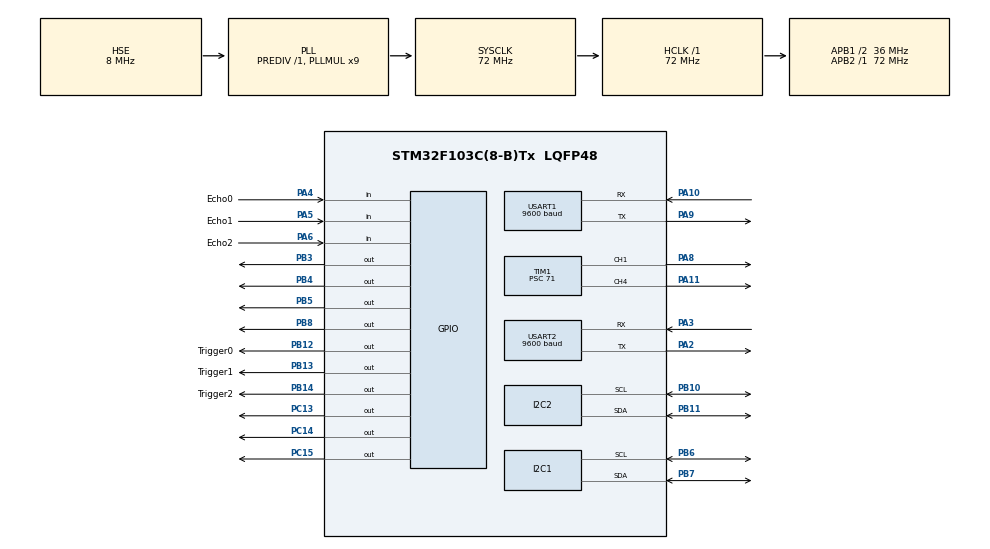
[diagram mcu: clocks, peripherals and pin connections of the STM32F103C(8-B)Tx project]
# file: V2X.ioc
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Mcu.Family=STM32F1
Mcu.Name=STM32F103C(8-B)Tx
Mcu.Package=LQFP48
NVIC.PriorityGroup=NVIC_PRIORITYGROUP_4
NVIC.TIM2_IRQn=true\:0\:0\:false\:false\:true\:true\:true\:true
NVIC.USART1_IRQn=true\:0\:0\:false\:false\:true\:true\:true\:true
PA10.Mode=Asynchronous
PA10.Signal=USART1_RX
PA11.Signal=S_TIM1_CH4
PA2.Mode=Asynchronous
PA2.Signal=USART2_TX
PA3.Mode=Asynchronous
PA3.Signal=USART2_RX
PA4.GPIO_Label=Echo0
PA4.Signal=GPIO_Input
PA5.GPIO_Label=Echo1
PA5.Signal=GPIO_Input
PA6.GPIO_Label=Echo2
PA6.Signal=GPIO_Input
PA8.Signal=S_TIM1_CH1
PA9.Mode=Asynchronous
PA9.Signal=USART1_TX
PB10.Mode=I2C
PB10.Signal=I2C2_SCL
PB11.Mode=I2C
PB11.Signal=I2C2_SDA
PB12.GPIO_Label=Trigger0
PB12.Signal=GPIO_Output
PB13.GPIO_Label=Trigger1
PB13.Signal=GPIO_Output
PB14.GPIO_Label=Trigger2
PB14.Signal=GPIO_Output
PB3.Signal=GPIO_Output
PB4.Signal=GPIO_Output
PB5.Signal=GPIO_Output
PB6.Mode=I2C
PB6.Signal=I2C1_SCL
PB7.Mode=I2C
PB7.Signal=I2C1_SDA
PB8.Signal=GPIO_Output
PC13-TAMPER-RTC.Signal=GPIO_Output
PC14-OSC32_IN.Signal=GPIO_Output
PC15-OSC32_OUT.Signal=GPIO_Output
PD0-OSC_IN.Mode=HSE-External-Oscillator
PD0-OSC_IN.Signal=RCC_OSC_IN
PD1-OSC_OUT.Mode=HSE-External-Oscillator
PD1-OSC_OUT.Signal=RCC_OSC_OUT
ProjectManager.HeapSize=0x200
ProjectManager.StackSize=0x400
ProjectManager.TargetToolchain=STM32CubeIDE
RCC.AHBFreq_Value=72000000
RCC.APB1CLKDivider=RCC_HCLK_DIV2
RCC.APB1Freq_Value=36000000
RCC.APB1TimFreq_Value=72000000
RCC.APB2Freq_Value=72000000
RCC.APB2TimFreq_Value=72000000
RCC.HCLKFreq_Value=72000000
RCC.PLLMUL=RCC_PLL_MUL9
RCC.PLLSourceVirtual=RCC_PLLSOURCE_HSE
RCC.SYSCLKFreq_VALUE=72000000
RCC.SYSCLKSource=RCC_SYSCLKSOURCE_PLLCLK
RCC.USBFreq_Value=72000000
SH.S_TIM1_CH1.0=TIM1_CH1,PWM Generation1 CH1
SH.S_TIM1_CH4.0=TIM1_CH4,PWM Generation4 CH4
TIM1.Channel-PWM\ Generation1\ CH1=TIM_CHANNEL_1
TIM1.Channel-PWM\ Generation4\ CH4=TIM_CHANNEL_4
TIM1.Period=999
TIM1.Prescaler=71
TIM2.Period=57
TIM2.Prescaler=72
USART1.BaudRate=9600
USART1.VirtualMode=VM_ASYNC
USART2.BaudRate=9600
USART2.VirtualMode=VM_ASYNC
VP_SYS_VS_ND.Mode=No_Debug
VP_TIM1_VS_ClockSourceINT.Mode=Internal
VP_TIM2_VS_ClockSourceINT.Mode=Internal
board=custom

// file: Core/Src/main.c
/* USER CODE BEGIN Header */
/**
 ******************************************************************************
 * @file           : main.c
 * @brief          : Main program body
 ******************************************************************************
 * @attention
 *
 * <h2><center>&copy; Copyright (c) 2020 STMicroelectronics.
 * All rights reserved.</center></h2>
 *
 * This software component is licensed by ST under BSD 3-Clause license,
 * the "License"; You may not use this file except in compliance with the
 * License. You may obtain a copy of the License at:
 *                        opensource.org/licenses/BSD-3-Clause
 *
 ******************************************************************************
 */
/* USER CODE END Header */
#include "main.h"

/* USER CODE BEGIN Includes */
#include "ACC.h"
#include "Ultrasonic.h"
#include "Motor.h"

/* USER CODE END Includes */

I2C_HandleTypeDef hi2c1;
I2C_HandleTypeDef hi2c2;

TIM_HandleTypeDef htim1;
TIM_HandleTypeDef htim2;

UART_HandleTypeDef huart1;
UART_HandleTypeDef huart2;

void SystemClock_Config(void);
static void MX_GPIO_Init(void);
static void MX_TIM2_Init(void);
static void MX_I2C1_Init(void);
static void MX_I2C2_Init(void);
static void MX_USART1_UART_Init(void);
static void MX_USART2_UART_Init(void);
static void MX_TIM1_Init(void);

int main(void)
{

	/* MCU Configuration--------------------------------------------------------*/

	/* Reset of all peripherals, Initializes the Flash interface and the Systick. */
	HAL_Init();

	/* Configure the system clock */
	SystemClock_Config();

	/* Initialize all configured peripherals */
	MX_GPIO_Init();
	MX_TIM2_Init();
	MX_I2C1_Init();
	MX_I2C2_Init();
	MX_USART1_UART_Init();
	MX_USART2_UART_Init();
	MX_TIM1_Init();
	/* USER CODE BEGIN 2 */
	// Initialize the ACC system
	      ACC_Init();

	      // Enable ACC with 70% target speed
	      ACC_Enable(70);

	      // Set following distance to 60cm
	      ACC_SetFollowingDistance(60);

	//		uint16_t distancesInCm[3];
	/* USER CODE END 2 */

	/* Infinite loop */
	/* USER CODE BEGIN WHILE */
	HAL_GPIO_WritePin(GPIOC, GPIO_PIN_13, GPIO_PIN_RESET);
	HAL_GPIO_WritePin(GPIOC, GPIO_PIN_14, GPIO_PIN_RESET);
	HAL_GPIO_WritePin(GPIOC, GPIO_PIN_15, GPIO_PIN_RESET);

	while (1)
	{
		/* USER CODE END WHILE */
		  ACC_Update();
		/* USER CODE BEGIN 3 */

		//				for(uint16_t i=0; i<3; i++)
		//				{
		//					sensor = i;//update sensor index in timer2
		//					distancesInCm[i] = measureDistance(triggerPorts[i], triggerPins[i], echoPorts[i], echoPins[i]);
		//					if (i==0&&distancesInCm[i]<40){
		//						HAL_GPIO_WritePin(GPIOC, GPIO_PIN_13, GPIO_PIN_SET);
		//						HAL_Delay(5000);
		//						HAL_GPIO_WritePin(GPIOC, GPIO_PIN_13, GPIO_PIN_RESET);
		//
		//					}
		//					if (i==1&&distancesInCm[i]<40){
		//						HAL_GPIO_WritePin(GPIOC, GPIO_PIN_14, GPIO_PIN_SET);
		//						HAL_Delay(5000);
		//						HAL_GPIO_WritePin(GPIOC, GPIO_PIN_14, GPIO_PIN_RESET);
		//
		//					}
		//					if (i==2&&distancesInCm[i]<40){
		//						HAL_GPIO_WritePin(GPIOC, GPIO_PIN_15, GPIO_PIN_SET);
		//						HAL_Delay(5000);
		//						HAL_GPIO_WritePin(GPIOC, GPIO_PIN_15, GPIO_PIN_RESET);
		//					}
		//
		//				}
		// Measure distances from all sensors
//		uint16_t front_dist = get_frontdis();
//		uint16_t left_dist = get_leftdis();
//		uint16_t right_dist = get_rightdis();
//		if (front_dist < 40) {
//			HAL_GPIO_WritePin(GPIOC, GPIO_PIN_13, GPIO_PIN_SET);
//			HAL_Delay(3000);
//			HAL_GPIO_WritePin(GPIOC, GPIO_PIN_13, GPIO_PIN_RESET);
//		}
//
//		// Left sensor logic
//		if (left_dist < 40) {
//			HAL_GPIO_WritePin(GPIOC, GPIO_PIN_14, GPIO_PIN_SET);
//			HAL_Delay(3000);
//			HAL_GPIO_WritePin(GPIOC, GPIO_PIN_14, GPIO_PIN_RESET);
//		}
//
//		// Right sensor logic
//		if (right_dist < 40) {
//			HAL_GPIO_WritePin(GPIOC, GPIO_PIN_15, GPIO_PIN_SET);
//			HAL_Delay(3000);
//			HAL_GPIO_WritePin(GPIOC, GPIO_PIN_15, GPIO_PIN_RESET);
//		}
//
//		// Small delay between measurements
//		HAL_Delay(100);

	}
	/* USER CODE END 3 */
}

void SystemClock_Config(void)
{
	RCC_OscInitTypeDef RCC_OscInitStruct = {0};
	RCC_ClkInitTypeDef RCC_ClkInitStruct = {0};

	/** Initializes the RCC Oscillators according to the specified parameters
	 * in the RCC_OscInitTypeDef structure.
	 */
	RCC_OscInitStruct.OscillatorType = RCC_OSCILLATORTYPE_HSE;
	RCC_OscInitStruct.HSEState = RCC_HSE_ON;
	RCC_OscInitStruct.HSEPredivValue = RCC_HSE_PREDIV_DIV1;
	RCC_OscInitStruct.HSIState = RCC_HSI_ON;
	RCC_OscInitStruct.PLL.PLLState = RCC_PLL_ON;
	RCC_OscInitStruct.PLL.PLLSource = RCC_PLLSOURCE_HSE;
	RCC_OscInitStruct.PLL.PLLMUL = RCC_PLL_MUL9;
	if (HAL_RCC_OscConfig(&RCC_OscInitStruct) != HAL_OK)
	{
		Error_Handler();
	}

	/** Initializes the CPU, AHB and APB buses clocks
	 */
	RCC_ClkInitStruct.ClockType = RCC_CLOCKTYPE_HCLK|RCC_CLOCKTYPE_SYSCLK
			|RCC_CLOCKTYPE_PCLK1|RCC_CLOCKTYPE_PCLK2;
	RCC_ClkInitStruct.SYSCLKSource = RCC_SYSCLKSOURCE_PLLCLK;
	RCC_ClkInitStruct.AHBCLKDivider = RCC_SYSCLK_DIV1;
	RCC_ClkInitStruct.APB1CLKDivider = RCC_HCLK_DIV2;
	RCC_ClkInitStruct.APB2CLKDivider = RCC_HCLK_DIV1;

	if (HAL_RCC_ClockConfig(&RCC_ClkInitStruct, FLASH_LATENCY_2) != HAL_OK)
	{
		Error_Handler();
	}
}

static void MX_I2C1_Init(void)
{

	hi2c1.Instance = I2C1;
	hi2c1.Init.ClockSpeed = 100000;
	hi2c1.Init.DutyCycle = I2C_DUTYCYCLE_2;
	hi2c1.Init.OwnAddress1 = 0;
	hi2c1.Init.AddressingMode = I2C_ADDRESSINGMODE_7BIT;
	hi2c1.Init.DualAddressMode = I2C_DUALADDRESS_DISABLE;
	hi2c1.Init.OwnAddress2 = 0;
	hi2c1.Init.GeneralCallMode = I2C_GENERALCALL_DISABLE;
	hi2c1.Init.NoStretchMode = I2C_NOSTRETCH_DISABLE;
	if (HAL_I2C_Init(&hi2c1) != HAL_OK)
	{
		Error_Handler();
	}

}

static void MX_I2C2_Init(void)
{

	hi2c2.Instance = I2C2;
	hi2c2.Init.ClockSpeed = 100000;
	hi2c2.Init.DutyCycle = I2C_DUTYCYCLE_2;
	hi2c2.Init.OwnAddress1 = 0;
	hi2c2.Init.AddressingMode = I2C_ADDRESSINGMODE_7BIT;
	hi2c2.Init.DualAddressMode = I2C_DUALADDRESS_DISABLE;
	hi2c2.Init.OwnAddress2 = 0;
	hi2c2.Init.GeneralCallMode = I2C_GENERALCALL_DISABLE;
	hi2c2.Init.NoStretchMode = I2C_NOSTRETCH_DISABLE;
	if (HAL_I2C_Init(&hi2c2) != HAL_OK)
	{
		Error_Handler();
	}

}

static void MX_TIM1_Init(void)
{

	TIM_ClockConfigTypeDef sClockSourceConfig = {0};
	TIM_MasterConfigTypeDef sMasterConfig = {0};
	TIM_OC_InitTypeDef sConfigOC = {0};
	TIM_BreakDeadTimeConfigTypeDef sBreakDeadTimeConfig = {0};

	htim1.Instance = TIM1;
	htim1.Init.Prescaler = 71;
	htim1.Init.CounterMode = TIM_COUNTERMODE_UP;
	htim1.Init.Period = 999;
	htim1.Init.ClockDivision = TIM_CLOCKDIVISION_DIV1;
	htim1.Init.RepetitionCounter = 0;
	htim1.Init.AutoReloadPreload = TIM_AUTORELOAD_PRELOAD_DISABLE;
	if (HAL_TIM_Base_Init(&htim1) != HAL_OK)
	{
		Error_Handler();
	}
	sClockSourceConfig.ClockSource = TIM_CLOCKSOURCE_INTERNAL;
	if (HAL_TIM_ConfigClockSource(&htim1, &sClockSourceConfig) != HAL_OK)
	{
		Error_Handler();
	}
	if (HAL_TIM_PWM_Init(&htim1) != HAL_OK)
	{
		Error_Handler();
	}
	sMasterConfig.MasterOutputTrigger = TIM_TRGO_RESET;
	sMasterConfig.MasterSlaveMode = TIM_MASTERSLAVEMODE_DISABLE;
	if (HAL_TIMEx_MasterConfigSynchronization(&htim1, &sMasterConfig) != HAL_OK)
	{
		Error_Handler();
	}
	sConfigOC.OCMode = TIM_OCMODE_PWM1;
	sConfigOC.Pulse = 0;
	sConfigOC.OCPolarity = TIM_OCPOLARITY_HIGH;
	sConfigOC.OCNPolarity = TIM_OCNPOLARITY_HIGH;
	sConfigOC.OCFastMode = TIM_OCFAST_DISABLE;
	sConfigOC.OCIdleState = TIM_OCIDLESTATE_RESET;
	sConfigOC.OCNIdleState = TIM_OCNIDLESTATE_RESET;
	if (HAL_TIM_PWM_ConfigChannel(&htim1, &sConfigOC, TIM_CHANNEL_1) != HAL_OK)
	{
		Error_Handler();
	}
	if (HAL_TIM_PWM_ConfigChannel(&htim1, &sConfigOC, TIM_CHANNEL_4) != HAL_OK)
	{
		Error_Handler();
	}
	sBreakDeadTimeConfig.OffStateRunMode = TIM_OSSR_DISABLE;
	sBreakDeadTimeConfig.OffStateIDLEMode = TIM_OSSI_DISABLE;
	sBreakDeadTimeConfig.LockLevel = TIM_LOCKLEVEL_OFF;
	sBreakDeadTimeConfig.DeadTime = 0;
	sBreakDeadTimeConfig.BreakState = TIM_BREAK_DISABLE;
	sBreakDeadTimeConfig.BreakPolarity = TIM_BREAKPOLARITY_HIGH;
	sBreakDeadTimeConfig.AutomaticOutput = TIM_AUTOMATICOUTPUT_DISABLE;
	if (HAL_TIMEx_ConfigBreakDeadTime(&htim1, &sBreakDeadTimeConfig) != HAL_OK)
	{
		Error_Handler();
	}
	HAL_TIM_MspPostInit(&htim1);

}

static void MX_TIM2_Init(void)
{

	TIM_ClockConfigTypeDef sClockSourceConfig = {0};
	TIM_MasterConfigTypeDef sMasterConfig = {0};

	htim2.Instance = TIM2;
	htim2.Init.Prescaler = 72;
	htim2.Init.CounterMode = TIM_COUNTERMODE_UP;
	htim2.Init.Period = 57;
	htim2.Init.ClockDivision = TIM_CLOCKDIVISION_DIV1;
	htim2.Init.AutoReloadPreload = TIM_AUTORELOAD_PRELOAD_DISABLE;
	if (HAL_TIM_Base_Init(&htim2) != HAL_OK)
	{
		Error_Handler();
	}
	sClockSourceConfig.ClockSource = TIM_CLOCKSOURCE_INTERNAL;
	if (HAL_TIM_ConfigClockSource(&htim2, &sClockSourceConfig) != HAL_OK)
	{
		Error_Handler();
	}
	sMasterConfig.MasterOutputTrigger = TIM_TRGO_RESET;
	sMasterConfig.MasterSlaveMode = TIM_MASTERSLAVEMODE_DISABLE;
	if (HAL_TIMEx_MasterConfigSynchronization(&htim2, &sMasterConfig) != HAL_OK)
	{
		Error_Handler();
	}

}

static void MX_USART1_UART_Init(void)
{

	huart1.Instance = USART1;
	huart1.Init.BaudRate = 9600;
	huart1.Init.WordLength = UART_WORDLENGTH_8B;
	huart1.Init.StopBits = UART_STOPBITS_1;
	huart1.Init.Parity = UART_PARITY_NONE;
	huart1.Init.Mode = UART_MODE_TX_RX;
	huart1.Init.HwFlowCtl = UART_HWCONTROL_NONE;
	huart1.Init.OverSampling = UART_OVERSAMPLING_16;
	if (HAL_UART_Init(&huart1) != HAL_OK)
	{
		Error_Handler();
	}

}

static void MX_USART2_UART_Init(void)
{

	huart2.Instance = USART2;
	huart2.Init.BaudRate = 9600;
	huart2.Init.WordLength = UART_WORDLENGTH_8B;
	huart2.Init.StopBits = UART_STOPBITS_1;
	huart2.Init.Parity = UART_PARITY_NONE;
	huart2.Init.Mode = UART_MODE_TX_RX;
	huart2.Init.HwFlowCtl = UART_HWCONTROL_NONE;
	huart2.Init.OverSampling = UART_OVERSAMPLING_16;
	if (HAL_UART_Init(&huart2) != HAL_OK)
	{
		Error_Handler();
	}

}

static void MX_GPIO_Init(void)
{
	GPIO_InitTypeDef GPIO_InitStruct = {0};

	/* GPIO Ports Clock Enable */
	__HAL_RCC_GPIOC_CLK_ENABLE();
	__HAL_RCC_GPIOD_CLK_ENABLE();
	__HAL_RCC_GPIOA_CLK_ENABLE();
	__HAL_RCC_GPIOB_CLK_ENABLE();

	/*Configure GPIO pin Output Level */
	HAL_GPIO_WritePin(GPIOC, GPIO_PIN_13|GPIO_PIN_14|GPIO_PIN_15, GPIO_PIN_RESET);

	/*Configure GPIO pin Output Level */
	HAL_GPIO_WritePin(GPIOB, Trigger0_Pin|Trigger1_Pin|Trigger2_Pin|GPIO_PIN_3
			|GPIO_PIN_4|GPIO_PIN_5|GPIO_PIN_8, GPIO_PIN_RESET);

	/*Configure GPIO pins : PC13 PC14 PC15 */
	GPIO_InitStruct.Pin = GPIO_PIN_13|GPIO_PIN_14|GPIO_PIN_15;
	GPIO_InitStruct.Mode = GPIO_MODE_OUTPUT_PP;
	GPIO_InitStruct.Pull = GPIO_NOPULL;
	GPIO_InitStruct.Speed = GPIO_SPEED_FREQ_LOW;
	HAL_GPIO_Init(GPIOC, &GPIO_InitStruct);

	/*Configure GPIO pins : Echo0_Pin Echo1_Pin Echo2_Pin */
	GPIO_InitStruct.Pin = Echo0_Pin|Echo1_Pin|Echo2_Pin;
	GPIO_InitStruct.Mode = GPIO_MODE_INPUT;
	GPIO_InitStruct.Pull = GPIO_NOPULL;
	HAL_GPIO_Init(GPIOA, &GPIO_InitStruct);

	/*Configure GPIO pins : Trigger0_Pin Trigger1_Pin Trigger2_Pin PB3
                           PB4 PB5 PB8 */
	GPIO_InitStruct.Pin = Trigger0_Pin|Trigger1_Pin|Trigger2_Pin|GPIO_PIN_3
			|GPIO_PIN_4|GPIO_PIN_5|GPIO_PIN_8;
	GPIO_InitStruct.Mode = GPIO_MODE_OUTPUT_PP;
	GPIO_InitStruct.Pull = GPIO_NOPULL;
	GPIO_InitStruct.Speed = GPIO_SPEED_FREQ_LOW;
	HAL_GPIO_Init(GPIOB, &GPIO_InitStruct);

}

void Error_Handler(void)
{
}
